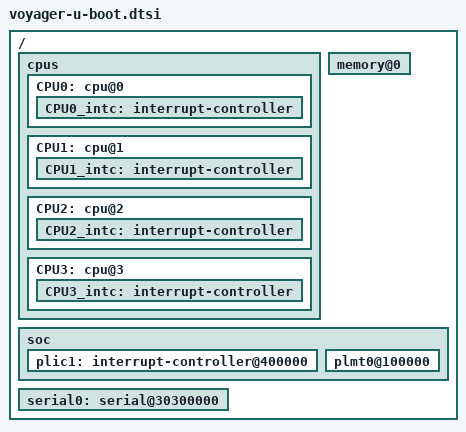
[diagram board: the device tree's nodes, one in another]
// SPDX-License-Identifier: (GPL-2.0 OR MIT)

/ {
	cpus {
		bootph-pre-ram;
		CPU0: cpu@0 {
			bootph-pre-ram;
			CPU0_intc: interrupt-controller {
				bootph-pre-ram;
			};
		};
		CPU1: cpu@1 {
			bootph-pre-ram;
			CPU1_intc: interrupt-controller {
				bootph-pre-ram;
			};
		};
		CPU2: cpu@2 {
			bootph-pre-ram;
			CPU2_intc: interrupt-controller {
				bootph-pre-ram;
			};
		};
		CPU3: cpu@3 {
			bootph-pre-ram;
			CPU3_intc: interrupt-controller {
				bootph-pre-ram;
			};
		};
	};

	memory@0 {
		bootph-pre-ram;
	};

	soc {
		bootph-pre-ram;

		plic1: interrupt-controller@400000 {
			bootph-pre-ram;
		};

		plmt0@100000 {
			bootph-pre-ram;
		};
	};

	serial0: serial@30300000 {
		bootph-pre-ram;
	};

};
